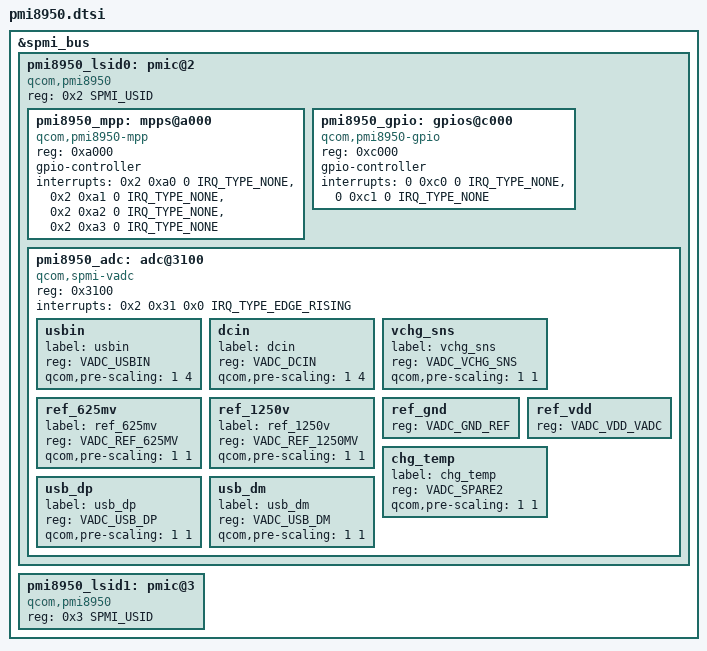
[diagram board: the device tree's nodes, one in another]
// SPDX-License-Identifier: GPL-2.0
// Copyright (c) 2019, AngeloGioacchino Del Regno <kholk11@gmail.com>

#include <dt-bindings/iio/qcom,spmi-vadc.h>
#include <dt-bindings/interrupt-controller/irq.h>
#include <dt-bindings/spmi/spmi.h>

&spmi_bus {
	pmi8950_lsid0: pmic@2 {
		compatible = "qcom,pmi8950", "qcom,spmi-pmic";
		reg = <0x2 SPMI_USID>;
		#address-cells = <1>;
		#size-cells = <0>;

		pmi8950_mpp: mpps@a000 {
			compatible = "qcom,pmi8950-mpp", "qcom,spmi-mpp";
			reg = <0xa000>;
			gpio-controller;
			#gpio-cells = <2>;
			interrupts = <0x2 0xa0 0 IRQ_TYPE_NONE>,
				<0x2 0xa1 0 IRQ_TYPE_NONE>,
				<0x2 0xa2 0 IRQ_TYPE_NONE>,
				<0x2 0xa3 0 IRQ_TYPE_NONE>;
		};

		pmi8950_gpio: gpios@c000 {
			compatible = "qcom,pmi8950-gpio", "qcom,spmi-gpio";
			reg = <0xc000>;
			gpio-controller;
			#gpio-cells = <2>;
			interrupts = <0 0xc0 0 IRQ_TYPE_NONE>,
				<0 0xc1 0 IRQ_TYPE_NONE>;
		};

		pmi8950_adc: adc@3100 {
			compatible = "qcom,spmi-vadc";
			reg = <0x3100>;
			interrupts = <0x2 0x31 0x0 IRQ_TYPE_EDGE_RISING>;
			#address-cells = <1>;
			#size-cells = <0>;
			#io-channel-cells = <1>;

			usbin {
				label = "usbin";
				reg = <VADC_USBIN>;
				qcom,pre-scaling = <1 4>;
			};
			dcin {
				label = "dcin";
				reg = <VADC_DCIN>;
				qcom,pre-scaling = <1 4>;
			};
			vchg_sns {
				label = "vchg_sns";
				reg = <VADC_VCHG_SNS>;
				qcom,pre-scaling = <1 1>;
			};
			ref_625mv {
				label = "ref_625mv";
				reg = <VADC_REF_625MV>;
				qcom,pre-scaling = <1 1>;
			};
			ref_1250v {
				label = "ref_1250v";
				reg = <VADC_REF_1250MV>;
				qcom,pre-scaling = <1 1>;
			};
			ref_gnd {
				reg = <VADC_GND_REF>;
			};
			ref_vdd {
				reg = <VADC_VDD_VADC>;
			};
			chg_temp {
				label = "chg_temp";
				reg = <VADC_SPARE2>;
				qcom,pre-scaling = <1 1>;
			};
			usb_dp {
				label = "usb_dp";
				reg = <VADC_USB_DP>;
				qcom,pre-scaling = <1 1>;
			};
			usb_dm {
				label = "usb_dm";
				reg = <VADC_USB_DM>;
				qcom,pre-scaling = <1 1>;
			};
		};
	};

	pmi8950_lsid1: pmic@3 {
		compatible = "qcom,pmi8950", "qcom,spmi-pmic";
		reg = <0x3 SPMI_USID>;
		#address-cells = <1>;
		#size-cells = <0>;
	};
};
